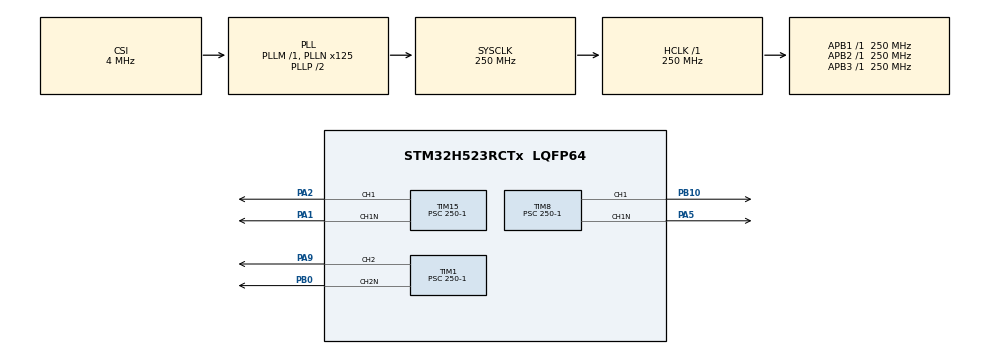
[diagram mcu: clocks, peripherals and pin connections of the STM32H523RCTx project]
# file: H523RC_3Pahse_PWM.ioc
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BOOTPATH.BootPathName=LEGACY
BOOTPATH.UserSelectedBootPath=LEGACY
CORTEX_M33_NS.userName=CORTEX_M33
Mcu.Family=STM32H5
Mcu.Name=STM32H523RCTx
Mcu.Package=LQFP64
NVIC.PriorityGroup=NVIC_PRIORITYGROUP_4
PA1.Mode=PWM Generation1 CH1 CH1N
PA1.Signal=TIM15_CH1N
PA2.Signal=S_TIM15_CH1
PA5.Mode=PWM Generation1 CH1 CH1N
PA5.Signal=TIM8_CH1N
PA9.Signal=S_TIM1_CH2
PB0.Mode=PWM Generation2 CH2 CH2N
PB0.Signal=TIM1_CH2N
PB10.Signal=S_TIM8_CH1
ProjectManager.HeapSize=0x200
ProjectManager.StackSize=0x400
ProjectManager.TargetToolchain=STM32CubeIDE
RCC.ADCFreq_Value=250000000
RCC.AHBFreq_Value=250000000
RCC.APB1Freq_Value=250000000
RCC.APB1TimFreq_Value=250000000
RCC.APB2Freq_Value=250000000
RCC.APB2TimFreq_Value=250000000
RCC.APB3Freq_Value=250000000
RCC.CSI_VALUE=4000000
RCC.CortexFreq_Value=250000000
RCC.EPOD_VALUE=4000000
RCC.HCLKFreq_Value=250000000
RCC.HSE_VALUE=25000000
RCC.HSI48_VALUE=48000000
RCC.HSI_VALUE=64000000
RCC.LSE_VALUE=32768
RCC.LSIRC_VALUE=32000
RCC.PLL2FRACN=0
RCC.PLL3FRACN=0
RCC.PLLFRACN=0
RCC.PLLN=125
RCC.SYSCLKFreq_VALUE=250000000
RCC.SYSCLKSource=RCC_SYSCLKSOURCE_PLLCLK
RCC.USBFreq_Value=48000000
RCC.VCOOutputFreq_Value=500000000
SH.S_TIM15_CH1.0=TIM15_CH1,PWM Generation1 CH1 CH1N
SH.S_TIM1_CH2.0=TIM1_CH2,PWM Generation2 CH2 CH2N
SH.S_TIM8_CH1.0=TIM8_CH1,PWM Generation1 CH1 CH1N
TIM1.Channel-Output\ Compare1\ No\ Output=TIM_CHANNEL_1
TIM1.Channel-PWM\ Generation2\ CH2\ CH2N=TIM_CHANNEL_2
TIM1.DeadTime=100
TIM1.OCMode_1=TIM_OCMODE_ACTIVE
TIM1.PeriodNoDither=10000-1
TIM1.Prescaler=250-1
TIM1.PulseNoDither_1=3333
TIM1.PulseNoDither_2=5000
TIM1.TIM_MasterOutputTrigger=TIM_TRGO_OC1REF
TIM15.Channel-PWM\ Generation1\ CH1\ CH1N=TIM_CHANNEL_1
TIM15.DeadTime=100
TIM15.DeadTimePreload=DISABLE
TIM15.PeriodNoDither=10000-1
TIM15.Prescaler=250-1
TIM15.PulseNoDither_1=5000
TIM8.Channel-Output\ Compare2\ No\ Output=TIM_CHANNEL_2
TIM8.Channel-PWM\ Generation1\ CH1\ CH1N=TIM_CHANNEL_1
TIM8.DeadTime=100
TIM8.DeadTimePreload=DISABLE
TIM8.OCMode_2=TIM_OCMODE_ACTIVE
TIM8.PeriodNoDither=10000-1
TIM8.Prescaler=250-1
TIM8.PulseNoDither_1=5000
TIM8.PulseNoDither_2=3333
TIM8.TIM_MasterOutputTrigger=TIM_TRGO_OC2REF
VP_BOOTPATH_VS_BOOTPATH.Mode=BP_Activate
VP_CORTEX_M33_NS_VS_Hclk.Mode=Hclk_Mode
VP_MEMORYMAP_VS_MEMORYMAP.Mode=CurAppReg
VP_PWR_VS_DBSignals.Mode=DisableDeadBatterySignals
VP_PWR_VS_LPOM.Mode=PowerOptimisation
VP_PWR_VS_SECSignals.Mode=Security/Privilege
VP_TIM15_VS_ClockSourceITR.Mode=TriggerSource_ITR5
VP_TIM15_VS_ControllerModeTrigger.Mode=Trigger Mode
VP_TIM1_VS_no_output1.Mode=Output Compare1 No Output
VP_TIM8_VS_ClockSourceITR.Mode=TriggerSource_ITR0
VP_TIM8_VS_ControllerModeTrigger.Mode=Trigger Mode
VP_TIM8_VS_no_output2.Mode=Output Compare2 No Output
board=custom

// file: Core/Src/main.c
/* USER CODE BEGIN Header */
/**
  ******************************************************************************
  * @file           : main.c
  * @brief          : Main program body
  ******************************************************************************
  * @attention
  *
  * Copyright (c) 2024 STMicroelectronics.
  * All rights reserved.
  *
  * This software is licensed under terms that can be found in the LICENSE file
  * in the root directory of this software component.
  * If no LICENSE file comes with this software, it is provided AS-IS.
  *
  ******************************************************************************
  */
/* USER CODE END Header */
#include "main.h"

TIM_HandleTypeDef htim1;
TIM_HandleTypeDef htim8;
TIM_HandleTypeDef htim15;

void SystemClock_Config(void);
static void MX_GPIO_Init(void);
static void MX_TIM1_Init(void);
static void MX_TIM8_Init(void);
static void MX_TIM15_Init(void);

int main(void)
{

  /* MCU Configuration--------------------------------------------------------*/

  /* Reset of all peripherals, Initializes the Flash interface and the Systick. */
  HAL_Init();

  /* Configure the system clock */
  SystemClock_Config();

  /* Initialize all configured peripherals */
  MX_GPIO_Init();
  MX_TIM1_Init();
  MX_TIM8_Init();
  MX_TIM15_Init();
  /* USER CODE BEGIN 2 */
  HAL_TIM_PWM_Start(&htim1, TIM_CHANNEL_2);
  HAL_TIMEx_PWMN_Start (&htim1, TIM_CHANNEL_2);
  HAL_TIM_OC_Start(&htim1, TIM_CHANNEL_1);

  HAL_TIM_PWM_Start(&htim8, TIM_CHANNEL_1);
  HAL_TIMEx_PWMN_Start (&htim8, TIM_CHANNEL_1);
  HAL_TIM_OC_Start(&htim8, TIM_CHANNEL_2);

  HAL_TIM_PWM_Start(&htim15, TIM_CHANNEL_1);
  HAL_TIMEx_PWMN_Start (&htim15, TIM_CHANNEL_1);

  /* USER CODE END 2 */

  /* Infinite loop */
  while (1)
  {

  }
}

void SystemClock_Config(void)
{
  RCC_OscInitTypeDef RCC_OscInitStruct = {0};
  RCC_ClkInitTypeDef RCC_ClkInitStruct = {0};

  /** Configure the main internal regulator output voltage
  */
  __HAL_PWR_VOLTAGESCALING_CONFIG(PWR_REGULATOR_VOLTAGE_SCALE0);

  while(!__HAL_PWR_GET_FLAG(PWR_FLAG_VOSRDY)) {}

  /** Initializes the RCC Oscillators according to the specified parameters
  * in the RCC_OscInitTypeDef structure.
  */
  RCC_OscInitStruct.OscillatorType = RCC_OSCILLATORTYPE_CSI;
  RCC_OscInitStruct.CSIState = RCC_CSI_ON;
  RCC_OscInitStruct.CSICalibrationValue = RCC_CSICALIBRATION_DEFAULT;
  RCC_OscInitStruct.PLL.PLLState = RCC_PLL_ON;
  RCC_OscInitStruct.PLL.PLLSource = RCC_PLL1_SOURCE_CSI;
  RCC_OscInitStruct.PLL.PLLM = 1;
  RCC_OscInitStruct.PLL.PLLN = 125;
  RCC_OscInitStruct.PLL.PLLP = 2;
  RCC_OscInitStruct.PLL.PLLQ = 2;
  RCC_OscInitStruct.PLL.PLLR = 2;
  RCC_OscInitStruct.PLL.PLLRGE = RCC_PLL1_VCIRANGE_2;
  RCC_OscInitStruct.PLL.PLLVCOSEL = RCC_PLL1_VCORANGE_WIDE;
  RCC_OscInitStruct.PLL.PLLFRACN = 0;
  if (HAL_RCC_OscConfig(&RCC_OscInitStruct) != HAL_OK)
  {
    Error_Handler();
  }

  /** Initializes the CPU, AHB and APB buses clocks
  */
  RCC_ClkInitStruct.ClockType = RCC_CLOCKTYPE_HCLK|RCC_CLOCKTYPE_SYSCLK
                              |RCC_CLOCKTYPE_PCLK1|RCC_CLOCKTYPE_PCLK2
                              |RCC_CLOCKTYPE_PCLK3;
  RCC_ClkInitStruct.SYSCLKSource = RCC_SYSCLKSOURCE_PLLCLK;
  RCC_ClkInitStruct.AHBCLKDivider = RCC_SYSCLK_DIV1;
  RCC_ClkInitStruct.APB1CLKDivider = RCC_HCLK_DIV1;
  RCC_ClkInitStruct.APB2CLKDivider = RCC_HCLK_DIV1;
  RCC_ClkInitStruct.APB3CLKDivider = RCC_HCLK_DIV1;

  if (HAL_RCC_ClockConfig(&RCC_ClkInitStruct, FLASH_LATENCY_5) != HAL_OK)
  {
    Error_Handler();
  }

  /** Configure the programming delay
  */
  __HAL_FLASH_SET_PROGRAM_DELAY(FLASH_PROGRAMMING_DELAY_2);
}

static void MX_TIM1_Init(void)
{

  TIM_MasterConfigTypeDef sMasterConfig = {0};
  TIM_OC_InitTypeDef sConfigOC = {0};
  TIM_BreakDeadTimeConfigTypeDef sBreakDeadTimeConfig = {0};

  htim1.Instance = TIM1;
  htim1.Init.Prescaler = 250-1;
  htim1.Init.CounterMode = TIM_COUNTERMODE_UP;
  htim1.Init.Period = 9999;
  htim1.Init.ClockDivision = TIM_CLOCKDIVISION_DIV1;
  htim1.Init.RepetitionCounter = 0;
  htim1.Init.AutoReloadPreload = TIM_AUTORELOAD_PRELOAD_DISABLE;
  if (HAL_TIM_OC_Init(&htim1) != HAL_OK)
  {
    Error_Handler();
  }
  if (HAL_TIM_PWM_Init(&htim1) != HAL_OK)
  {
    Error_Handler();
  }
  sMasterConfig.MasterOutputTrigger = TIM_TRGO_OC1REF;
  sMasterConfig.MasterOutputTrigger2 = TIM_TRGO2_RESET;
  sMasterConfig.MasterSlaveMode = TIM_MASTERSLAVEMODE_DISABLE;
  if (HAL_TIMEx_MasterConfigSynchronization(&htim1, &sMasterConfig) != HAL_OK)
  {
    Error_Handler();
  }
  sConfigOC.OCMode = TIM_OCMODE_ACTIVE;
  sConfigOC.Pulse = 3333;
  sConfigOC.OCPolarity = TIM_OCPOLARITY_HIGH;
  sConfigOC.OCNPolarity = TIM_OCNPOLARITY_HIGH;
  sConfigOC.OCFastMode = TIM_OCFAST_DISABLE;
  sConfigOC.OCIdleState = TIM_OCIDLESTATE_RESET;
  sConfigOC.OCNIdleState = TIM_OCNIDLESTATE_RESET;
  if (HAL_TIM_OC_ConfigChannel(&htim1, &sConfigOC, TIM_CHANNEL_1) != HAL_OK)
  {
    Error_Handler();
  }
  sConfigOC.OCMode = TIM_OCMODE_PWM1;
  sConfigOC.Pulse = 5000;
  if (HAL_TIM_PWM_ConfigChannel(&htim1, &sConfigOC, TIM_CHANNEL_2) != HAL_OK)
  {
    Error_Handler();
  }
  sBreakDeadTimeConfig.OffStateRunMode = TIM_OSSR_DISABLE;
  sBreakDeadTimeConfig.OffStateIDLEMode = TIM_OSSI_DISABLE;
  sBreakDeadTimeConfig.LockLevel = TIM_LOCKLEVEL_OFF;
  sBreakDeadTimeConfig.DeadTime = 100;
  sBreakDeadTimeConfig.BreakState = TIM_BREAK_DISABLE;
  sBreakDeadTimeConfig.BreakPolarity = TIM_BREAKPOLARITY_HIGH;
  sBreakDeadTimeConfig.BreakFilter = 0;
  sBreakDeadTimeConfig.BreakAFMode = TIM_BREAK_AFMODE_INPUT;
  sBreakDeadTimeConfig.Break2State = TIM_BREAK2_DISABLE;
  sBreakDeadTimeConfig.Break2Polarity = TIM_BREAK2POLARITY_HIGH;
  sBreakDeadTimeConfig.Break2Filter = 0;
  sBreakDeadTimeConfig.Break2AFMode = TIM_BREAK_AFMODE_INPUT;
  sBreakDeadTimeConfig.AutomaticOutput = TIM_AUTOMATICOUTPUT_DISABLE;
  if (HAL_TIMEx_ConfigBreakDeadTime(&htim1, &sBreakDeadTimeConfig) != HAL_OK)
  {
    Error_Handler();
  }
  HAL_TIM_MspPostInit(&htim1);

}

static void MX_TIM8_Init(void)
{

  TIM_SlaveConfigTypeDef sSlaveConfig = {0};
  TIM_MasterConfigTypeDef sMasterConfig = {0};
  TIM_OC_InitTypeDef sConfigOC = {0};
  TIM_BreakDeadTimeConfigTypeDef sBreakDeadTimeConfig = {0};

  htim8.Instance = TIM8;
  htim8.Init.Prescaler = 250-1;
  htim8.Init.CounterMode = TIM_COUNTERMODE_UP;
  htim8.Init.Period = 9999;
  htim8.Init.ClockDivision = TIM_CLOCKDIVISION_DIV1;
  htim8.Init.RepetitionCounter = 0;
  htim8.Init.AutoReloadPreload = TIM_AUTORELOAD_PRELOAD_DISABLE;
  if (HAL_TIM_Base_Init(&htim8) != HAL_OK)
  {
    Error_Handler();
  }
  if (HAL_TIM_PWM_Init(&htim8) != HAL_OK)
  {
    Error_Handler();
  }
  if (HAL_TIM_OC_Init(&htim8) != HAL_OK)
  {
    Error_Handler();
  }
  sSlaveConfig.SlaveMode = TIM_SLAVEMODE_TRIGGER;
  sSlaveConfig.InputTrigger = TIM_TS_ITR0;
  if (HAL_TIM_SlaveConfigSynchro(&htim8, &sSlaveConfig) != HAL_OK)
  {
    Error_Handler();
  }
  sMasterConfig.MasterOutputTrigger = TIM_TRGO_OC2REF;
  sMasterConfig.MasterOutputTrigger2 = TIM_TRGO2_RESET;
  sMasterConfig.MasterSlaveMode = TIM_MASTERSLAVEMODE_DISABLE;
  if (HAL_TIMEx_MasterConfigSynchronization(&htim8, &sMasterConfig) != HAL_OK)
  {
    Error_Handler();
  }
  sConfigOC.OCMode = TIM_OCMODE_PWM1;
  sConfigOC.Pulse = 5000;
  sConfigOC.OCPolarity = TIM_OCPOLARITY_HIGH;
  sConfigOC.OCNPolarity = TIM_OCNPOLARITY_HIGH;
  sConfigOC.OCFastMode = TIM_OCFAST_DISABLE;
  sConfigOC.OCIdleState = TIM_OCIDLESTATE_RESET;
  sConfigOC.OCNIdleState = TIM_OCNIDLESTATE_RESET;
  if (HAL_TIM_PWM_ConfigChannel(&htim8, &sConfigOC, TIM_CHANNEL_1) != HAL_OK)
  {
    Error_Handler();
  }
  sConfigOC.OCMode = TIM_OCMODE_ACTIVE;
  sConfigOC.Pulse = 3333;
  if (HAL_TIM_OC_ConfigChannel(&htim8, &sConfigOC, TIM_CHANNEL_2) != HAL_OK)
  {
    Error_Handler();
  }
  sBreakDeadTimeConfig.OffStateRunMode = TIM_OSSR_DISABLE;
  sBreakDeadTimeConfig.OffStateIDLEMode = TIM_OSSI_DISABLE;
  sBreakDeadTimeConfig.LockLevel = TIM_LOCKLEVEL_OFF;
  sBreakDeadTimeConfig.DeadTime = 100;
  sBreakDeadTimeConfig.BreakState = TIM_BREAK_DISABLE;
  sBreakDeadTimeConfig.BreakPolarity = TIM_BREAKPOLARITY_HIGH;
  sBreakDeadTimeConfig.BreakFilter = 0;
  sBreakDeadTimeConfig.BreakAFMode = TIM_BREAK_AFMODE_INPUT;
  sBreakDeadTimeConfig.Break2State = TIM_BREAK2_DISABLE;
  sBreakDeadTimeConfig.Break2Polarity = TIM_BREAK2POLARITY_HIGH;
  sBreakDeadTimeConfig.Break2Filter = 0;
  sBreakDeadTimeConfig.Break2AFMode = TIM_BREAK_AFMODE_INPUT;
  sBreakDeadTimeConfig.AutomaticOutput = TIM_AUTOMATICOUTPUT_DISABLE;
  if (HAL_TIMEx_ConfigBreakDeadTime(&htim8, &sBreakDeadTimeConfig) != HAL_OK)
  {
    Error_Handler();
  }
  HAL_TIM_MspPostInit(&htim8);

}

static void MX_TIM15_Init(void)
{

  TIM_SlaveConfigTypeDef sSlaveConfig = {0};
  TIM_MasterConfigTypeDef sMasterConfig = {0};
  TIM_OC_InitTypeDef sConfigOC = {0};
  TIM_BreakDeadTimeConfigTypeDef sBreakDeadTimeConfig = {0};

  htim15.Instance = TIM15;
  htim15.Init.Prescaler = 250-1;
  htim15.Init.CounterMode = TIM_COUNTERMODE_UP;
  htim15.Init.Period = 9999;
  htim15.Init.ClockDivision = TIM_CLOCKDIVISION_DIV1;
  htim15.Init.RepetitionCounter = 0;
  htim15.Init.AutoReloadPreload = TIM_AUTORELOAD_PRELOAD_DISABLE;
  if (HAL_TIM_Base_Init(&htim15) != HAL_OK)
  {
    Error_Handler();
  }
  if (HAL_TIM_PWM_Init(&htim15) != HAL_OK)
  {
    Error_Handler();
  }
  sSlaveConfig.SlaveMode = TIM_SLAVEMODE_TRIGGER;
  sSlaveConfig.InputTrigger = TIM_TS_ITR5;
  if (HAL_TIM_SlaveConfigSynchro(&htim15, &sSlaveConfig) != HAL_OK)
  {
    Error_Handler();
  }
  sMasterConfig.MasterOutputTrigger = TIM_TRGO_RESET;
  sMasterConfig.MasterSlaveMode = TIM_MASTERSLAVEMODE_DISABLE;
  if (HAL_TIMEx_MasterConfigSynchronization(&htim15, &sMasterConfig) != HAL_OK)
  {
    Error_Handler();
  }
  sConfigOC.OCMode = TIM_OCMODE_PWM1;
  sConfigOC.Pulse = 5000;
  sConfigOC.OCPolarity = TIM_OCPOLARITY_HIGH;
  sConfigOC.OCNPolarity = TIM_OCNPOLARITY_HIGH;
  sConfigOC.OCFastMode = TIM_OCFAST_DISABLE;
  sConfigOC.OCIdleState = TIM_OCIDLESTATE_RESET;
  sConfigOC.OCNIdleState = TIM_OCNIDLESTATE_RESET;
  if (HAL_TIM_PWM_ConfigChannel(&htim15, &sConfigOC, TIM_CHANNEL_1) != HAL_OK)
  {
    Error_Handler();
  }
  sBreakDeadTimeConfig.OffStateRunMode = TIM_OSSR_DISABLE;
  sBreakDeadTimeConfig.OffStateIDLEMode = TIM_OSSI_DISABLE;
  sBreakDeadTimeConfig.LockLevel = TIM_LOCKLEVEL_OFF;
  sBreakDeadTimeConfig.DeadTime = 100;
  sBreakDeadTimeConfig.BreakState = TIM_BREAK_DISABLE;
  sBreakDeadTimeConfig.BreakPolarity = TIM_BREAKPOLARITY_HIGH;
  sBreakDeadTimeConfig.BreakFilter = 0;
  sBreakDeadTimeConfig.AutomaticOutput = TIM_AUTOMATICOUTPUT_DISABLE;
  if (HAL_TIMEx_ConfigBreakDeadTime(&htim15, &sBreakDeadTimeConfig) != HAL_OK)
  {
    Error_Handler();
  }
  HAL_TIM_MspPostInit(&htim15);

}

static void MX_GPIO_Init(void)
{

  /* GPIO Ports Clock Enable */
  __HAL_RCC_GPIOA_CLK_ENABLE();
  __HAL_RCC_GPIOB_CLK_ENABLE();

}

void Error_Handler(void)
{
  __disable_irq();
  while (1)
  {
  }
}
